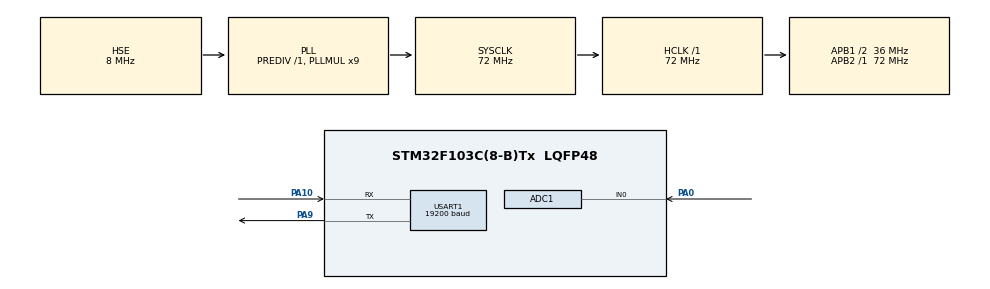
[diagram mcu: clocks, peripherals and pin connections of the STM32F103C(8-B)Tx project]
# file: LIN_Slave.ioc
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ADC1.Channel-0\#ChannelRegularConversion=ADC_CHANNEL_0
ADC1.NbrOfConversionFlag=1
ADC1.Rank-0\#ChannelRegularConversion=1
ADC1.SamplingTime-0\#ChannelRegularConversion=ADC_SAMPLETIME_239CYCLES_5
ADC1.master=1
Mcu.Family=STM32F1
Mcu.Name=STM32F103C(8-B)Tx
Mcu.Package=LQFP48
NVIC.PriorityGroup=NVIC_PRIORITYGROUP_4
PA0-WKUP.Signal=ADCx_IN0
PA10.Mode=LIN
PA10.Signal=USART1_RX
PA13.Mode=Serial_Wire
PA13.Signal=SYS_JTMS-SWDIO
PA14.Mode=Serial_Wire
PA14.Signal=SYS_JTCK-SWCLK
PA9.Mode=LIN
PA9.Signal=USART1_TX
PD0-OSC_IN.Mode=HSE-External-Oscillator
PD0-OSC_IN.Signal=RCC_OSC_IN
PD1-OSC_OUT.Mode=HSE-External-Oscillator
PD1-OSC_OUT.Signal=RCC_OSC_OUT
ProjectManager.HeapSize=0x200
ProjectManager.StackSize=0x400
ProjectManager.TargetToolchain=STM32CubeIDE
RCC.ADCPresc=RCC_ADCPCLK2_DIV6
RCC.AHBFreq_Value=72000000
RCC.APB1CLKDivider=RCC_HCLK_DIV2
RCC.APB1Freq_Value=36000000
RCC.APB1TimFreq_Value=72000000
RCC.APB2Freq_Value=72000000
RCC.APB2TimFreq_Value=72000000
RCC.HCLKFreq_Value=72000000
RCC.PLLMUL=RCC_PLL_MUL9
RCC.PLLSourceVirtual=RCC_PLLSOURCE_HSE
RCC.SYSCLKFreq_VALUE=72000000
RCC.SYSCLKSource=RCC_SYSCLKSOURCE_PLLCLK
RCC.USBFreq_Value=72000000
SH.ADCx_IN0.0=ADC1_IN0,IN0
USART1.BaudRate=19200
USART1.BreakDetectLength=UART_LINBREAKDETECTLENGTH_11B
USART1.VirtualMode=VM_ASYNC
board=custom

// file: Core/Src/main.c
/* USER CODE BEGIN Header */
/**
  ******************************************************************************
  * @file           : main.c
  * @brief          : Main program body
  ******************************************************************************
  * @attention
  *
  * Copyright (c) 2026 STMicroelectronics.
  * All rights reserved.
  *
  * This software is licensed under terms that can be found in the LICENSE file
  * in the root directory of this software component.
  * If no LICENSE file comes with this software, it is provided AS-IS.
  *
  ******************************************************************************
  */
/* USER CODE END Header */
#include "main.h"

/* USER CODE BEGIN Includes */
#include <string.h>
/* USER CODE END Includes */

ADC_HandleTypeDef hadc1;

UART_HandleTypeDef huart1;

void SystemClock_Config(void);
static void MX_GPIO_Init(void);
static void MX_ADC1_Init(void);
static void MX_USART1_UART_Init(void);
/* USER CODE BEGIN PFP */
static uint8_t lin_checksum(const uint8_t *data, uint8_t len);
static uint16_t ADC_Read(void);
static uint8_t lin_wait_header(void);
/* USER CODE END PFP */

/* USER CODE BEGIN 0 */
/* Classic LIN checksum: inverted carry-around sum of data bytes */
static uint8_t lin_checksum(const uint8_t *data, uint8_t len)
{
  uint16_t sum = 0;

  for (uint8_t i = 0; i < len; i++)
  {
    sum += data[i];
    if (sum > 0xFF)
    {
      sum -= 0xFF;
    }
  }

  return (uint8_t)(~sum & 0xFF);
}

/* Blocking single ADC conversion */
static uint16_t ADC_Read(void)
{
  HAL_ADC_Start(&hadc1);
  HAL_ADC_PollForConversion(&hadc1, HAL_MAX_DELAY);
  uint16_t v = (uint16_t)HAL_ADC_GetValue(&hadc1);
  HAL_ADC_Stop(&hadc1);

  return v;
}

/*
 * Wait for LIN sync byte 0x55 then read the PID.
 * Any framing-error bytes received during the break field
 * are silently discarded until 0x55 is seen.
 * Returns PID on success, 0xFF on timeout.
 */
static uint8_t lin_wait_header(void)
{
  uint8_t byte;

  /* Drain until sync byte 0x55 */
  while (1)
  {
    if (HAL_UART_Receive(&huart1, &byte, 1, 200) != HAL_OK)
    {
      return 0xFF;   /* timeout */
    }

    if (byte == 0x55)
    {
      break;
    }
  }

  /* Next byte is the PID */
  if (HAL_UART_Receive(&huart1, &byte, 1, 50) != HAL_OK)
  {
    return 0xFF;
  }

  return byte;
}
/* USER CODE END 0 */

int main(void)
{

  /* MCU Configuration--------------------------------------------------------*/

  /* Reset of all peripherals, Initializes the Flash interface and the Systick. */
  HAL_Init();

  /* Configure the system clock */
  SystemClock_Config();

  /* Initialize all configured peripherals */
  MX_GPIO_Init();
  MX_ADC1_Init();
  MX_USART1_UART_Init();
  /* USER CODE BEGIN 2 */
uint8_t tx_buf[3];
  uint16_t adc_val;
/* USER CODE END 2 */

  /* Infinite loop */
  /* USER CODE BEGIN WHILE */
while (1)
  {
    uint8_t pid = lin_wait_header();

    if (pid == 0x01)    /* frame ID we publish */
    {
      adc_val = ADC_Read();

      tx_buf[0] = (uint8_t)(adc_val >> 8);
      tx_buf[1] = (uint8_t)(adc_val & 0xFF);
      tx_buf[2] = lin_checksum(tx_buf, 2);

      HAL_UART_Transmit(&huart1, tx_buf, 3, HAL_MAX_DELAY);
    }

    /* All other PIDs are ignored */
/* USER CODE END WHILE */

  }
}

void SystemClock_Config(void)
{
  RCC_OscInitTypeDef RCC_OscInitStruct = {0};
  RCC_ClkInitTypeDef RCC_ClkInitStruct = {0};
  RCC_PeriphCLKInitTypeDef PeriphClkInit = {0};

  /** Initializes the RCC Oscillators according to the specified parameters
  * in the RCC_OscInitTypeDef structure.
  */
  RCC_OscInitStruct.OscillatorType = RCC_OSCILLATORTYPE_HSE;
  RCC_OscInitStruct.HSEState = RCC_HSE_ON;
  RCC_OscInitStruct.HSEPredivValue = RCC_HSE_PREDIV_DIV1;
  RCC_OscInitStruct.HSIState = RCC_HSI_ON;
  RCC_OscInitStruct.PLL.PLLState = RCC_PLL_ON;
  RCC_OscInitStruct.PLL.PLLSource = RCC_PLLSOURCE_HSE;
  RCC_OscInitStruct.PLL.PLLMUL = RCC_PLL_MUL9;
  if (HAL_RCC_OscConfig(&RCC_OscInitStruct) != HAL_OK)
  {
    Error_Handler();
  }

  /** Initializes the CPU, AHB and APB buses clocks
  */
  RCC_ClkInitStruct.ClockType = RCC_CLOCKTYPE_HCLK|RCC_CLOCKTYPE_SYSCLK
                              |RCC_CLOCKTYPE_PCLK1|RCC_CLOCKTYPE_PCLK2;
  RCC_ClkInitStruct.SYSCLKSource = RCC_SYSCLKSOURCE_PLLCLK;
  RCC_ClkInitStruct.AHBCLKDivider = RCC_SYSCLK_DIV1;
  RCC_ClkInitStruct.APB1CLKDivider = RCC_HCLK_DIV2;
  RCC_ClkInitStruct.APB2CLKDivider = RCC_HCLK_DIV1;

  if (HAL_RCC_ClockConfig(&RCC_ClkInitStruct, FLASH_LATENCY_2) != HAL_OK)
  {
    Error_Handler();
  }
  PeriphClkInit.PeriphClockSelection = RCC_PERIPHCLK_ADC;
  PeriphClkInit.AdcClockSelection = RCC_ADCPCLK2_DIV6;
  if (HAL_RCCEx_PeriphCLKConfig(&PeriphClkInit) != HAL_OK)
  {
    Error_Handler();
  }
}

static void MX_ADC1_Init(void)
{

  ADC_ChannelConfTypeDef sConfig = {0};

  /** Common config
  */
  hadc1.Instance = ADC1;
  hadc1.Init.ScanConvMode = ADC_SCAN_DISABLE;
  hadc1.Init.ContinuousConvMode = DISABLE;
  hadc1.Init.DiscontinuousConvMode = DISABLE;
  hadc1.Init.ExternalTrigConv = ADC_SOFTWARE_START;
  hadc1.Init.DataAlign = ADC_DATAALIGN_RIGHT;
  hadc1.Init.NbrOfConversion = 1;
  if (HAL_ADC_Init(&hadc1) != HAL_OK)
  {
    Error_Handler();
  }

  /** Configure Regular Channel
  */
  sConfig.Channel = ADC_CHANNEL_0;
  sConfig.Rank = ADC_REGULAR_RANK_1;
  sConfig.SamplingTime = ADC_SAMPLETIME_239CYCLES_5;
  if (HAL_ADC_ConfigChannel(&hadc1, &sConfig) != HAL_OK)
  {
    Error_Handler();
  }

}

static void MX_USART1_UART_Init(void)
{

  huart1.Instance = USART1;
  huart1.Init.BaudRate = 19200;
  huart1.Init.WordLength = UART_WORDLENGTH_8B;
  huart1.Init.StopBits = UART_STOPBITS_1;
  huart1.Init.Parity = UART_PARITY_NONE;
  huart1.Init.Mode = UART_MODE_TX_RX;
  huart1.Init.HwFlowCtl = UART_HWCONTROL_NONE;
  if (HAL_LIN_Init(&huart1, UART_LINBREAKDETECTLENGTH_11B) != HAL_OK)
  {
    Error_Handler();
  }

}

static void MX_GPIO_Init(void)
{

  /* GPIO Ports Clock Enable */
  __HAL_RCC_GPIOD_CLK_ENABLE();
  __HAL_RCC_GPIOA_CLK_ENABLE();

}

void Error_Handler(void)
{
  __disable_irq();
  while (1)
  {
  }
}
